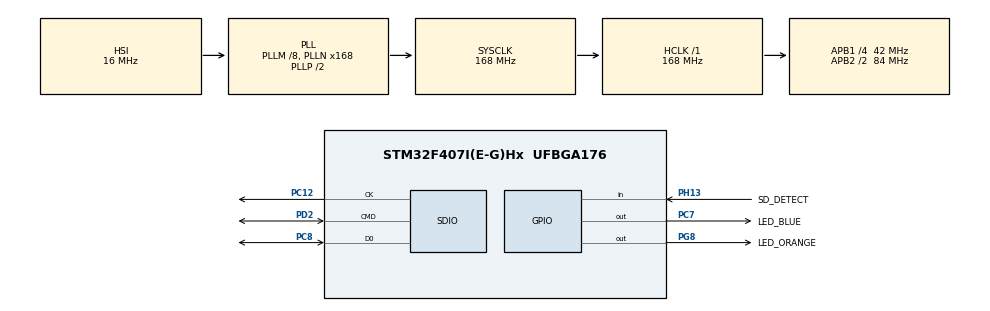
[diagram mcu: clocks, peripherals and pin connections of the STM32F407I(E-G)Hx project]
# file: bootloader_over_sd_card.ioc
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FATFS.BSP.number=1
FATFS._USE_LFN=1
FATFS0.BSP.STBoard=false
FATFS0.BSP.api=Unknown
FATFS0.BSP.i2caddr=0
FATFS0.BSP.instance=PH13
FATFS0.BSP.ip=GPIO
FATFS0.BSP.mode=Input
FATFS0.BSP.name=Detect_SDIO
FATFS0.BSP.solution=PH13
Mcu.Family=STM32F4
Mcu.Name=STM32F407I(E-G)Hx
Mcu.Package=UFBGA176
NVIC.PriorityGroup=NVIC_PRIORITYGROUP_4
PA13.Mode=JTAG_5_pins
PA13.Signal=SYS_JTMS-SWDIO
PA14.Mode=JTAG_5_pins
PA14.Signal=SYS_JTCK-SWCLK
PA15.Mode=JTAG_5_pins
PA15.Signal=SYS_JTDI
PB3.Mode=JTAG_5_pins
PB3.Signal=SYS_JTDO-SWO
PB4.Mode=JTAG_5_pins
PB4.Signal=SYS_JTRST
PC12.Mode=SD_1_bit
PC12.Signal=SDIO_CK
PC7.GPIO_Label=LED_BLUE
PC7.GPIO_PuPd=GPIO_PULLDOWN
PC7.Signal=GPIO_Output
PC8.Mode=SD_1_bit
PC8.Signal=SDIO_D0
PD2.Mode=SD_1_bit
PD2.Signal=SDIO_CMD
PG8.GPIO_Label=LED_ORANGE
PG8.Signal=GPIO_Output
PH13.GPIO_Label=SD_DETECT
PH13.GPIO_PuPd=GPIO_PULLUP
PH13.Signal=GPIO_Input
ProjectManager.HeapSize=0x200
ProjectManager.StackSize=0x400
ProjectManager.TargetToolchain=STM32CubeIDE
RCC.48MHZClocksFreq_Value=48000000
RCC.AHBFreq_Value=168000000
RCC.APB1CLKDivider=RCC_HCLK_DIV4
RCC.APB1Freq_Value=42000000
RCC.APB1TimFreq_Value=84000000
RCC.APB2CLKDivider=RCC_HCLK_DIV2
RCC.APB2Freq_Value=84000000
RCC.APB2TimFreq_Value=168000000
RCC.CortexFreq_Value=168000000
RCC.HCLKFreq_Value=168000000
RCC.HSE_VALUE=25000000
RCC.HSI_VALUE=16000000
RCC.LSE_VALUE=32768
RCC.PLLM=8
RCC.PLLN=168
RCC.PLLQ=7
RCC.SYSCLKFreq_VALUE=168000000
RCC.SYSCLKSource=RCC_SYSCLKSOURCE_PLLCLK
RCC.VCOOutputFreq_Value=336000000
VP_FATFS_VS_SDIO.Mode=SDIO
board=custom

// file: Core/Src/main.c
/* USER CODE BEGIN Header */
/**
  ******************************************************************************
  * @file           : main.c
  * @brief          : Main program body
  ******************************************************************************
  * @attention
  *
  * <h2><center>&copy; Copyright (c) 2020 STMicroelectronics.
  * All rights reserved.</center></h2>
  *
  * This software component is licensed by ST under BSD 3-Clause license,
  * the "License"; You may not use this file except in compliance with the
  * License. You may obtain a copy of the License at:
  *                        opensource.org/licenses/BSD-3-Clause
  *
  ******************************************************************************
  */
/* USER CODE END Header */

#include "main.h"
#include "fatfs.h"
#include "sdio.h"
#include "gpio.h"

/* USER CODE BEGIN Includes */
#include <stdio.h>
#include "bl.h"
/* USER CODE END Includes */

void SystemClock_Config(void);

int main(void)
{

  /* MCU Configuration--------------------------------------------------------*/

  /* Reset of all peripherals, Initializes the Flash interface and the Systick. */
  HAL_Init();

  /* Configure the system clock */
  SystemClock_Config();

  /* Initialize all configured peripherals */
  MX_GPIO_Init();
  MX_SDIO_SD_Init();
  MX_FATFS_Init();

  /* Infinite loop */
  while (1)
  {

    /* USER CODE BEGIN 3 */
	  bl_machine(&bl);
  }
  /* USER CODE END 3 */
}

void SystemClock_Config(void)
{
  RCC_OscInitTypeDef RCC_OscInitStruct = {0};
  RCC_ClkInitTypeDef RCC_ClkInitStruct = {0};

  /** Configure the main internal regulator output voltage
  */
  __HAL_RCC_PWR_CLK_ENABLE();
  __HAL_PWR_VOLTAGESCALING_CONFIG(PWR_REGULATOR_VOLTAGE_SCALE1);
  /** Initializes the CPU, AHB and APB busses clocks
  */
  RCC_OscInitStruct.OscillatorType = RCC_OSCILLATORTYPE_HSI;
  RCC_OscInitStruct.HSIState = RCC_HSI_ON;
  RCC_OscInitStruct.HSICalibrationValue = RCC_HSICALIBRATION_DEFAULT;
  RCC_OscInitStruct.PLL.PLLState = RCC_PLL_ON;
  RCC_OscInitStruct.PLL.PLLSource = RCC_PLLSOURCE_HSI;
  RCC_OscInitStruct.PLL.PLLM = 8;
  RCC_OscInitStruct.PLL.PLLN = 168;
  RCC_OscInitStruct.PLL.PLLP = RCC_PLLP_DIV2;
  RCC_OscInitStruct.PLL.PLLQ = 7;
  if (HAL_RCC_OscConfig(&RCC_OscInitStruct) != HAL_OK)
  {
    Error_Handler();
  }
  /** Initializes the CPU, AHB and APB busses clocks
  */
  RCC_ClkInitStruct.ClockType = RCC_CLOCKTYPE_HCLK|RCC_CLOCKTYPE_SYSCLK
                              |RCC_CLOCKTYPE_PCLK1|RCC_CLOCKTYPE_PCLK2;
  RCC_ClkInitStruct.SYSCLKSource = RCC_SYSCLKSOURCE_PLLCLK;
  RCC_ClkInitStruct.AHBCLKDivider = RCC_SYSCLK_DIV1;
  RCC_ClkInitStruct.APB1CLKDivider = RCC_HCLK_DIV4;
  RCC_ClkInitStruct.APB2CLKDivider = RCC_HCLK_DIV2;

  if (HAL_RCC_ClockConfig(&RCC_ClkInitStruct, FLASH_LATENCY_5) != HAL_OK)
  {
    Error_Handler();
  }
}

void Error_Handler(void)
{
}

/************************ (C) COPYRIGHT STMicroelectronics *****END OF FILE****/
